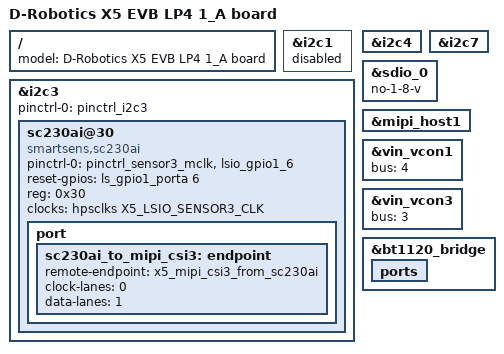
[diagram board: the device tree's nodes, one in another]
// SPDX-License-Identifier: GPL-2.0
/*
 * dts for Sunrise5 EVB LP4 1_A board
 *
 * Copyright (C) 2024 D-Robotics Inc.
 *
 */

/dts-v1/;
#include "x5-evb.dtsi"

/ {
	model = "D-Robotics X5 EVB LP4 1_A board";
};

&i2c1 {
	status = "disabled";
};

&i2c3 {
	status = "okay";
	pinctrl-names = "default";
	pinctrl-0 = <&pinctrl_i2c3>;

	sc230ai@30 {
		status = "okay";
		compatible = "smartsens,sc230ai";
		pinctrl-names = "default";
		pinctrl-0 = <&pinctrl_sensor3_mclk &lsio_gpio1_6>;
		reset-gpios = <&ls_gpio1_porta 6 GPIO_ACTIVE_HIGH>;	/* HIGH is ACTIVE LEVEL */
		reg = <0x30>;
		clocks = <&hpsclks X5_LSIO_SENSOR3_CLK>;
		clock-names = "xclk";

		port {
			/* MIPI CSI-2 bus endpoint */
			sc230ai_to_mipi_csi3: endpoint {
				remote-endpoint = <&x5_mipi_csi3_from_sc230ai>;
				clock-lanes = <0>;
				data-lanes = <1>;	//1 lane
			};
		};
	};
};

&i2c4 {
	/delete-node/ lt8618@3b;
};

&i2c7 {
	/delete-node/ sc230ai@30;
};

/* SD Card */
&sdio_0 {
	no-1-8-v;
};

&mipi_host1 {
	status = "okay";
	//in x5-evb, mipi host0 & host1 share one mclk and gpio
};

&vin_vcon1 {
	status = "okay";
	//use same sensor gpio with vcon0 and i2c bus
	/delete-property/ pinctrl-names;
	/delete-property/ pinctrl-0;
	/delete-property/ gpio_oth;
	bus = <4>;
	/delete-property/ lpwm_chn;
	//lpwm_chn = <1>; //open lpwm0 - channel1
	//use same lpwm0 with vcon0
};

&vin_vcon3 {
	bus = <3>;  //i2c3
};


&bt1120_bridge {
	ports {
		/delete-node/ port@1;
	};
};
